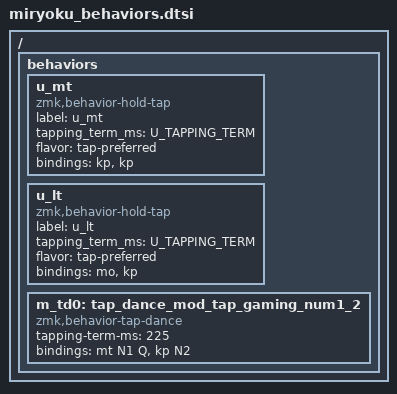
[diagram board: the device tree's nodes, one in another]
// Copyright 2022 Manna Harbour
// https://github.com/manna-harbour/miryoku

/ {
  behaviors {
    u_mt: u_mt {
      compatible = "zmk,behavior-hold-tap";
      label = "u_mt";
      #binding-cells = <2>;
      tapping_term_ms = <U_TAPPING_TERM>;
      flavor = "tap-preferred";
      bindings = <&kp>, <&kp>;
    };
    u_lt: u_lt {
      compatible = "zmk,behavior-hold-tap";
      label = "u_lt";
      #binding-cells = <2>;
      tapping_term_ms = <U_TAPPING_TERM>;
      flavor = "tap-preferred";
      bindings = <&mo>, <&kp>;
    };
    m_td0: tap_dance_mod_tap_gaming_num1_2 {
      compatible = "zmk,behavior-tap-dance";
      #binding-cells = <0>;
      tapping-term-ms = <225>;
      bindings = <&mt N1 Q>, <&kp N2>;
    };
  };
};
